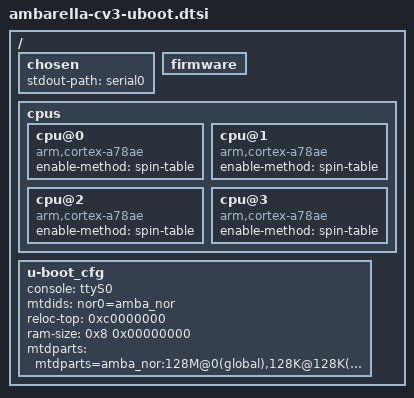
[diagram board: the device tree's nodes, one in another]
/ {
	chosen: chosen {
		stdout-path = "serial0";
	};

	/delete-node/ psci;

	firmware {
		/delete-node/ optee;
	};

	cpus {
		cpu@0 {
			compatible = "arm,cortex-a78ae", "arm,cortex-a76", "arm,armv8";
			enable-method = "spin-table";
		};

		/*specify cpu_release_addr+0x8 at amba_bld.map*/
		cpu@1 {
			compatible = "arm,cortex-a78ae", "arm,cortex-a76", "arm,armv8";
			enable-method = "spin-table";
		};

		/*specify cpu_release_addr+0x10 at amba_bld.map*/
		cpu@2 {
			compatible = "arm,cortex-a78ae", "arm,cortex-a76", "arm,armv8";
			enable-method = "spin-table";
		};

		/*specify cpu_release_addr+0x18 at amba_bld.map*/
		cpu@3 {
			compatible = "arm,cortex-a78ae", "arm,cortex-a76", "arm,armv8";
			enable-method = "spin-table";
		};
	};

	u-boot_cfg {
		console = "ttyS0";
		mtdids = "nor0=amba_nor";
		reloc-top = <0xc0000000>;
		ram-size = <0x8 0x00000000>;
		mtdparts = "mtdparts=amba_nor:128M@0(global),128K@128K(ptb),1280K@256K(uboot),20M@36352K(kernel),62M@56832K(rootfs),1M@120320K(calib),256K@121344K(pref),128K@121600K(dtb)";
	};
};
